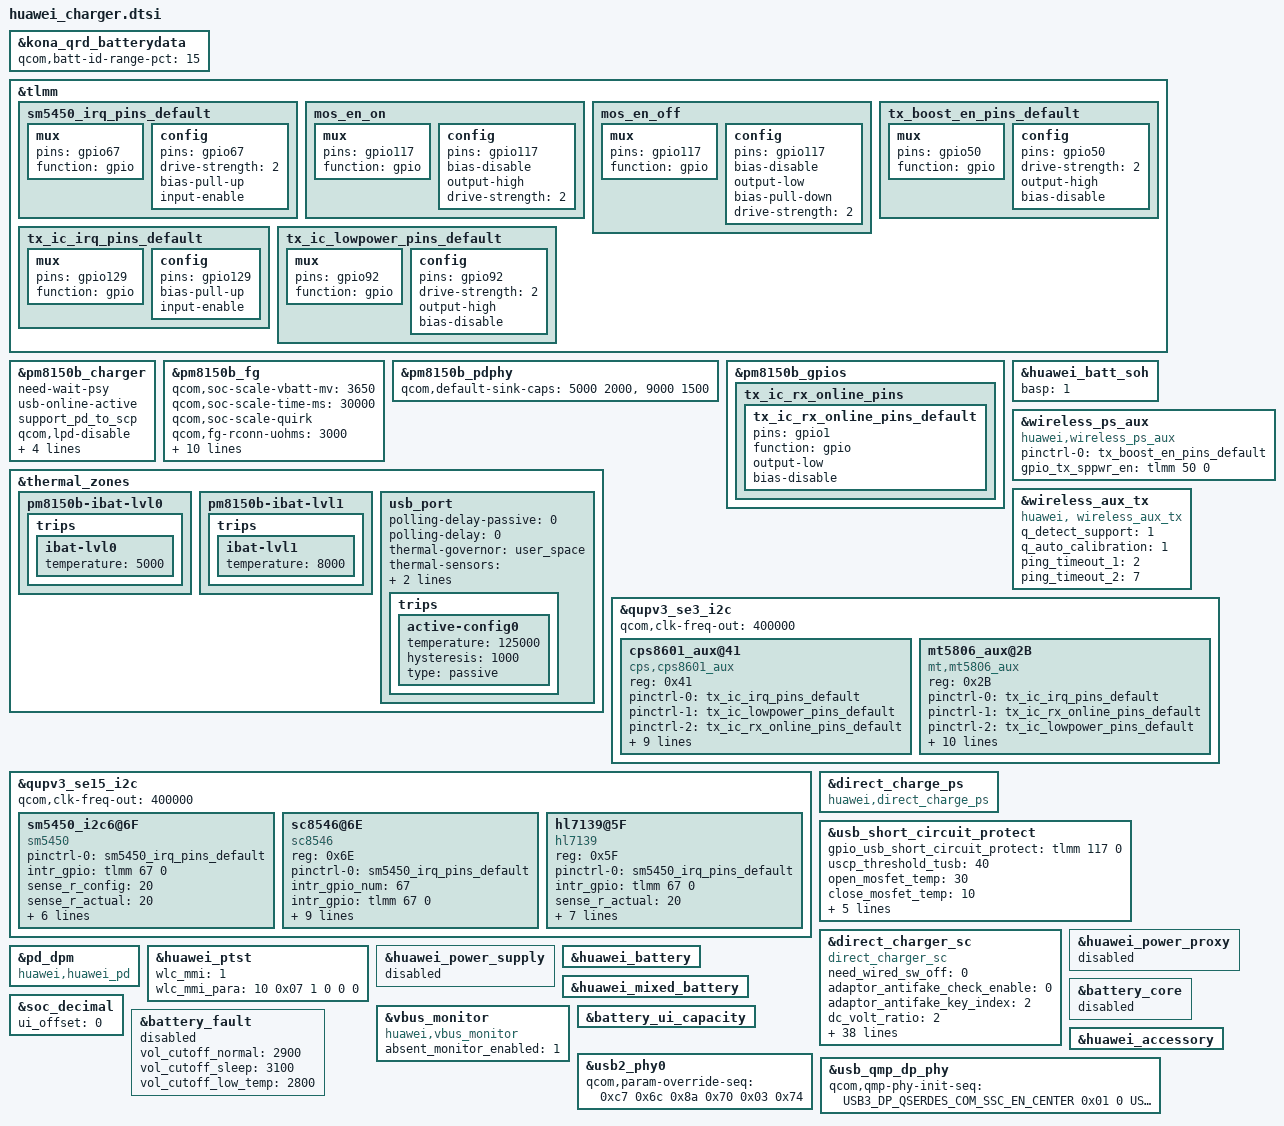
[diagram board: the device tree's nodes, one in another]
#include <dt-bindings/clock/qcom,gcc-kona.h>
#include <dt-bindings/phy/qcom,kona-qmp-usb3.h>

&kona_qrd_batterydata {
	qcom,batt-id-range-pct = <15>;
	#include "../../../huawei_charger/fg-gen4-batterydata-desayatl_7150_110k.dtsi"
	#include "../../../huawei_charger/fg-gen4-batterydata-sunwodacosmx_7150_200k.dtsi"
};

&tlmm {
	sm5450_irq_pins_default: sm5450_irq_pins_default {
		mux {
			pins = "gpio67";
			function = "gpio";
		};
		config {
			pins = "gpio67";
			drive-strength = <2>;
			bias-pull-up;
			input-enable;
		};
	};

	mos_en_on: mos_en_on {
		mux {
			pins = "gpio117";
			function = "gpio";
		};

		config {
			pins = "gpio117";
			bias-disable;
			output-high;
			drive-strength = <2>; /* 2 MA */
		};
	};

	mos_en_off: mos_en_off {
		mux {
			pins = "gpio117";
			function = "gpio";
		};

		config {
			pins = "gpio117";
			bias-disable;
			output-low;
			bias-pull-down; /* PULL DOWN */
			drive-strength = <2>; /* 2 MA */
		};
	};

	tx_boost_en_pins_default: tx_boost_en_pins_default {
		mux {
			pins = "gpio50";
			function = "gpio";
		};
		config {
			pins = "gpio50";
			drive-strength = <2>;
			output-high;
			bias-disable;
		};
	};

	tx_ic_irq_pins_default: tx_ic_irq_pins_default {
		mux {
			pins = "gpio129";
			function = "gpio";
		};
		config {
			pins = "gpio129";
			bias-pull-up;
			input-enable;
		};
	};

	tx_ic_lowpower_pins_default: tx_ic_lowpower_pins_default {
		mux {
			pins = "gpio92";
			function = "gpio";
		};
		config {
			pins = "gpio92";
			drive-strength = <2>;
			output-high;
			bias-disable;
		};
	};
};

&pm8150b_charger {
	need-wait-psy;
	usb-online-active;
	support_pd_to_scp;
	qcom,lpd-disable;
	qcom,otg-cl-ua = <1500000>;
	qcom,chg-term-current-ma = <(-178)>;
	qcom,auto-recharge-soc = <98>;
	qcom,auto-recharge-vbat-mv = <4250>;
};

&pm8150b_fg{
	qcom,soc-scale-vbatt-mv = <3650>;
	qcom,soc-scale-time-ms = <30000>;
	qcom,soc-scale-quirk;
	qcom,fg-rconn-uohms = <3000>;
	qcom,fg-cutoff-voltage = <3450>;
	qcom,slope-limit-temp-threshold = <100>;
	qcom,slope-limit-coeffs = <2500 2500 2500 500>;
        qcom,fg-force-load-profile;
	soc-temp-filt;
	qcom,soc-hi-res;
	qcom,fg-sys-term-current = <(-600)>;
	io-channels = <&pm8150b_vadc ADC_BAT_THERM_PU1>;
	io-channel-names = "batt_therm";
	qcom,fg-temp-ir-for-current = <7500 55 6500 55 5500 55 4500 55 3500 50 2500 40 1500 30 500 20 0 10>;
};

&pm8150b_pdphy {
	qcom,default-sink-caps = <5000 2000>, /* 5V @ 2A */
				 <9000 1500>; /* 9V @ 2A */
};

&pm8150b_gpios {
	tx_ic_rx_online_pins {
		tx_ic_rx_online_pins_default: tx_ic_rx_online_pins_default {
				pins = "gpio1";
				function = "gpio";
				output-low;
				bias-disable;
		};
	};
};

&huawei_batt_soh {
	basp = <1>;
	status = "ok";
};

&thermal_zones {
	pm8150b-ibat-lvl0 {
		trips {
			ibat-lvl0 {
				temperature = <5000>;
			};
		};
	};

	pm8150b-ibat-lvl1 {
		trips {
			ibat-lvl1 {
				temperature = <8000>;
			};
		};
	};
};

&wireless_ps_aux {
	compatible = "huawei,wireless_ps_aux";
	pinctrl-names = "default";
	pinctrl-0 = <&tx_boost_en_pins_default>;
	gpio_tx_sppwr_en = <&tlmm 50 0>;
	status = "ok";
};

&wireless_aux_tx {
	compatible = "huawei, wireless_aux_tx";
	q_detect_support = <1>;
	q_auto_calibration = <1>;
	ping_timeout_1 = <2>;
	ping_timeout_2 = <7>;
	status = "ok";
};

&qupv3_se3_i2c {
	#address-cells = <1>;
	#size-cells = <0>;
	qcom,clk-freq-out = <400000>;
	status = "ok";

	cps8601_aux@41 {
		compatible = "cps,cps8601_aux";
		reg = <0x41>;
		pinctrl-names = "irq", "lowpower", "rx_online";
		pinctrl-0 = <&tx_ic_irq_pins_default>;
		pinctrl-1 = <&tx_ic_lowpower_pins_default>;
		pinctrl-2 = <&tx_ic_rx_online_pins_default>;
		interrupt-parent = <&tlmm>;
		interrupts = <129 0>;
		gpio_int = <&tlmm 129 0>;
		gpio_lowpower = <&tlmm 92 0>;
		gpio_rx_online = <&pm8150b_gpios 1 0>;
		tx_min_fop = /bits/ 16 <120>;
		tx_max_fop = /bits/ 16 <145>;
		tx_ploss_th0 = /bits/ 16 <2500>;
		tx_ploss_cnt = /bits/ 8 <5>;
		status = "ok";
	};

	mt5806_aux@2B {
		compatible = "mt,mt5806_aux";
		reg = <0x2B>;
		pinctrl-names = "irq", "lowpower", "rx_online";
		pinctrl-0 = <&tx_ic_irq_pins_default>;
		pinctrl-1 = <&tx_ic_rx_online_pins_default>;
		pinctrl-2 = <&tx_ic_lowpower_pins_default>;
		interrupt-parent = <&tlmm>;
		interrupts = <129 0>;
		gpio_int = <&tlmm 129 0>;
		gpio_lowpower = <&tlmm 92 0>;
		gpio_rx_online = <&pm8150b_gpios 1 0>;
		tx_ping_ocp_th = <800>;
		tx_min_fop = /bits/ 16 <120>;
		tx_max_fop = /bits/ 16 <145>;
		tx_ploss_th0 = /bits/ 16 <2500>;
		tx_ploss_cnt = /bits/ 8 <5>;
		status = "ok";
	};
};

&qupv3_se15_i2c {
	#address-cells = <1>;
	#size-cells = <0>;
	qcom,clk-freq-out = <400000>; /* if bq27z561_fg is used, i2c clock must be 100k(100000) */
	status = "ok";

	sm5450_i2c6@6F {
		compatible = "sm5450";
		pinctrl-names = "default";
		pinctrl-0 = <&sm5450_irq_pins_default>;
		intr_gpio = <&tlmm 67 0>;
		sense_r_config = <20>;
		sense_r_actual = <20>;
		fcp_support = <1>;
		scp_support = <1>;
		close_ibat_ocp = <1>;
		sc_ibus_ocp = <4000>;
		switching_frequency = <675>;
		reg = <0x6F>;
		status = "ok";
	};

	sc8546@6E {
		compatible = "sc8546";
		reg = <0x6E>;
		pinctrl-names = "default";
		pinctrl-0 = <&sm5450_irq_pins_default>;
		intr_gpio_num = <67>; /* direct defined GPIO num */
		intr_gpio = <&tlmm 67 0>;
		fcp_support = <1>;
		scp_support = <1>;
		ufcs_support = <1>;
		sense_r_actual = <20>;
		i2c_recovery = <1>;
		i2c_recovery_addr = <0x6F>;
		switching_frequency = <850>;
		switching_frequency_shift = <1>;
		ic_role = <0>;
		status = "ok";
	};

	hl7139@5F {
		compatible = "hl7139";
		reg = <0x5F>;
		pinctrl-names = "default";
		pinctrl-0 = <&sm5450_irq_pins_default>;
		intr_gpio = <&tlmm 67 0>;
		sense_r_actual = <20>;
		fcp_support = <1>;
		scp_support = <1>;
		sc_ibus_ocp = <4000>;
		close_ibat_ocp = <1>;
		ignore_discharge_flag = <1>;
		switching_frequency = <500>;
		ic_role = <0>;
		status = "ok";
	};
};

&direct_charge_ps {
	compatible = "huawei,direct_charge_ps";
	status = "ok";
};

&thermal_zones {
	usb_port {
		polling-delay-passive = <0>;
		polling-delay = <0>;
		thermal-governor = "user_space";
		thermal-sensors = <&pm8150b_adc_tm ADC_AMUX_THM3_PU2>;
		wake-capable-sensor;
		trips {
			active-config0 {
				temperature = <125000>;
				hysteresis = <1000>;
				type = "passive";
			};
		};
	};
};

&usb_short_circuit_protect {
	gpio_usb_short_circuit_protect = <&tlmm 117 0>;
	uscp_threshold_tusb = <40>;
	open_mosfet_temp = <30>;
	close_mosfet_temp = <10>;
	open_hiz_temp = <30>;
	interval_switch_temp = <15>;
	use_pinctrl; /* use pinctrl to open or close mos */
	pinctrl-names = "mos_en_on", "mos_en_off";
	pinctrl-0 = <&mos_en_on>;
	pinctrl-1 = <&mos_en_off>;
	status = "ok";
};

&direct_charger_sc{
	compatible = "direct_charger_sc";
	need_wired_sw_off = <0>;
	adaptor_antifake_check_enable = <0>;
	adaptor_antifake_key_index = <2>;
	dc_volt_ratio = <2>;
	max_adaptor_vset = <11000>;
	max_tadapt = <115>;
	max_tls = <115>;
	ibat_abnormal_th = <200>;
	first_cc_stage_timer_in_min = <10>;
	max_dc_bat_vol = <4380>;
	min_dc_bat_vol = <3550>;
	charge_control_interval = <5>;
	threshold_caculation_interval = <5>;
	safety_monitor_interval = <5>;
	scp_work_on_charger = <1>;
	init_adapter_vset = <8800>;
	init_delt_vset = <450>;
	init_delt_iset = <1000>;
	vstep = <20>;
	delta_err = <300>;
	vol_err_th = <500>;
	full_path_res_max = <500>;
	ctc_cable_full_path_res_max = <400>;
	standard_cable_full_path_res_max = <500>;
	max_current_for_none_standard_cable = <6000>;
	adaptor_leakage_current_th = <300>;
	stage_need_to_jump = "-1";
	compensate_r = <0>;
	cc_cable_detect_enable = <1>;
	cc_unsafe_sc_enable = <1>;
	is_show_ico_first = <1>;
	delta_err_10v2p25a = <150>;
	gain_curr_10v2a = <300>;
	volt_para =
		"4130", "5000", "4000",
		"4220", "5000", "4000",
		"4280", "4000", "2800",
		"4420", "2800", "1200";
	temp_para =
		"-32767", "10", "0",
		"10", "45", "5000",
		"45", "32767", "0";
	10v2p25a_cur_para =
		"-32767", "5500",  "2250",
		"5500",   "9000",  "2500",
		"9000",   "10000", "2250",
		"10000",  "10500", "2250",
		"10500",  "32767", "1500";
	resist_para =
		"0", "300", "6000",
		"300", "500", "4000";
	std_resist_para =
		"0", "300", "8200",
		"300", "500", "4000";
	status = "ok";
};

&huawei_power_proxy {
	status = "disabled";
};

&pd_dpm {
	compatible = "huawei,huawei_pd";
	status = "ok";
};

&huawei_ptst {
	wlc_mmi = <1>;
	wlc_mmi_para = <10 0x07 1 0 0 0>;
	status = "ok";
};

&huawei_power_supply {
	status = "disabled";
};

&huawei_battery {
	status = "ok";
};

&huawei_mixed_battery {
	status = "ok";
};

&battery_core {
	status = "disabled";
};

&vbus_monitor {
	compatible = "huawei,vbus_monitor";
	absent_monitor_enabled = <1>;
	status = "ok";
};

&battery_ui_capacity {
	status = "ok";
};

&soc_decimal {
	ui_offset = <0>;
	status = "ok";
};

&battery_fault {
	vol_cutoff_normal = <2900>;
	vol_cutoff_sleep = <3100>;
	vol_cutoff_low_temp = <2800>;
	status = "disabled";
};

&huawei_accessory {
	status = "ok";
};

&usb2_phy0 {
	qcom,param-override-seq =
		<0xc7 0x6c
		0x8a 0x70
		0x03 0x74>;
};

&usb_qmp_dp_phy {
		qcom,qmp-phy-init-seq =
			/* <reg_offset, value, delay> */
			<USB3_DP_QSERDES_COM_SSC_EN_CENTER 0x01 0
			USB3_DP_QSERDES_COM_SSC_PER1 0x31 0
			USB3_DP_QSERDES_COM_SSC_PER2 0x01 0
			USB3_DP_QSERDES_COM_SSC_STEP_SIZE1_MODE0 0xDE 0
			USB3_DP_QSERDES_COM_SSC_STEP_SIZE2_MODE0 0x07 0
			USB3_DP_QSERDES_COM_SSC_STEP_SIZE1_MODE1 0xDE 0
			USB3_DP_QSERDES_COM_SSC_STEP_SIZE2_MODE1 0x07 0
			USB3_DP_QSERDES_COM_SYSCLK_BUF_ENABLE 0x0A 0
			USB3_DP_QSERDES_COM_CMN_IPTRIM 0x20 0
			USB3_DP_QSERDES_COM_CP_CTRL_MODE0 0x06 0
			USB3_DP_QSERDES_COM_CP_CTRL_MODE1 0x06 0
			USB3_DP_QSERDES_COM_PLL_RCTRL_MODE0 0x16 0
			USB3_DP_QSERDES_COM_PLL_RCTRL_MODE1 0x16 0
			USB3_DP_QSERDES_COM_PLL_CCTRL_MODE0 0x36 0
			USB3_DP_QSERDES_COM_PLL_CCTRL_MODE1 0x36 0
			USB3_DP_QSERDES_COM_SYSCLK_EN_SEL 0x1A 0
			USB3_DP_QSERDES_COM_LOCK_CMP_EN 0x04 0
			USB3_DP_QSERDES_COM_LOCK_CMP1_MODE0 0x14 0
			USB3_DP_QSERDES_COM_LOCK_CMP2_MODE0 0x34 0
			USB3_DP_QSERDES_COM_LOCK_CMP1_MODE1 0x34 0
			USB3_DP_QSERDES_COM_LOCK_CMP2_MODE1 0x82 0
			USB3_DP_QSERDES_COM_DEC_START_MODE0 0x82 0
			USB3_DP_QSERDES_COM_DEC_START_MODE1 0x82 0
			USB3_DP_QSERDES_COM_DIV_FRAC_START1_MODE0 0xAB 0
			USB3_DP_QSERDES_COM_DIV_FRAC_START2_MODE0 0xEA 0
			USB3_DP_QSERDES_COM_DIV_FRAC_START3_MODE0 0x02 0
			USB3_DP_QSERDES_COM_DIV_FRAC_START1_MODE1 0xAB 0
			USB3_DP_QSERDES_COM_DIV_FRAC_START2_MODE1 0xEA 0
			USB3_DP_QSERDES_COM_DIV_FRAC_START3_MODE1 0x02 0
			USB3_DP_QSERDES_COM_VCO_TUNE_MAP 0x02 0
			USB3_DP_QSERDES_COM_VCO_TUNE1_MODE0 0x24 0
			USB3_DP_QSERDES_COM_VCO_TUNE1_MODE1 0x24 0
			USB3_DP_QSERDES_COM_VCO_TUNE2_MODE1 0x02 0
			USB3_DP_QSERDES_COM_HSCLK_SEL 0x01 0
			USB3_DP_QSERDES_COM_CORECLK_DIV_MODE1 0x08 0
			USB3_DP_QSERDES_COM_BIN_VCOCAL_CMP_CODE1_MODE0 0xCA 0
			USB3_DP_QSERDES_COM_BIN_VCOCAL_CMP_CODE2_MODE0 0x1E 0
			USB3_DP_QSERDES_COM_BIN_VCOCAL_CMP_CODE1_MODE1 0xCA 0
			USB3_DP_QSERDES_COM_BIN_VCOCAL_CMP_CODE2_MODE1 0x1E 0
			USB3_DP_QSERDES_COM_BIN_VCOCAL_HSCLK_SEL 0x11 0
			USB3_DP_QSERDES_TXA_RES_CODE_LANE_TX 0x60 0
			USB3_DP_QSERDES_TXA_RES_CODE_LANE_RX 0x60 0
			USB3_DP_QSERDES_TXA_RES_CODE_LANE_OFFSET_TX 0x11 0
			USB3_DP_QSERDES_TXA_RES_CODE_LANE_OFFSET_RX 0x02 0
			USB3_DP_QSERDES_TXA_TX_EMP_POST1_LVL 0x3C 0
			USB3_DP_QSERDES_TXA_TX_DRV_LVL 0x3F 0
			USB3_DP_QSERDES_TXA_LANE_MODE_1 0xD5 0
			USB3_DP_QSERDES_TXA_LANE_MODE_2 0x00 0
			USB3_DP_QSERDES_TXA_RCV_DETECT_LVL_2 0x12 0
			USB3_DP_QSERDES_TXA_PI_QEC_CTRL 0x40 0
			USB3_DP_QSERDES_RXA_UCDR_FO_GAIN 0x09 0
			USB3_DP_QSERDES_RXA_UCDR_SO_GAIN 0x05 0
			USB3_DP_QSERDES_RXA_UCDR_FASTLOCK_FO_GAIN 0x2F 0
			USB3_DP_QSERDES_RXA_UCDR_SO_SATURATION_AND_ENABLE 0x7F 0
			USB3_DP_QSERDES_RXA_UCDR_FASTLOCK_COUNT_LOW 0xFF 0
			USB3_DP_QSERDES_RXA_UCDR_FASTLOCK_COUNT_HIGH 0x0F 0
			USB3_DP_QSERDES_RXA_UCDR_PI_CONTROLS 0x99 0
			USB3_DP_QSERDES_RXA_UCDR_SB2_THRESH1 0x08 0
			USB3_DP_QSERDES_RXA_UCDR_SB2_THRESH2 0x08 0
			USB3_DP_QSERDES_RXA_UCDR_SB2_GAIN1 0x00 0
			USB3_DP_QSERDES_RXA_UCDR_SB2_GAIN2 0x04 0
			USB3_DP_QSERDES_RXA_VGA_CAL_CNTRL1 0x54 0
			USB3_DP_QSERDES_RXA_VGA_CAL_CNTRL2 0x0C 0
			USB3_DP_QSERDES_RXA_RX_EQU_ADAPTOR_CNTRL2 0x0F 0
			USB3_DP_QSERDES_RXA_RX_EQU_ADAPTOR_CNTRL3 0x4A 0
			USB3_DP_QSERDES_RXA_RX_EQU_ADAPTOR_CNTRL4 0x0A 0
			USB3_DP_QSERDES_RXA_RX_IDAC_TSETTLE_LOW 0xC0 0
			USB3_DP_QSERDES_RXA_RX_IDAC_TSETTLE_HIGH 0x00 0
			USB3_DP_QSERDES_RXA_RX_EQ_OFFSET_ADAPTOR_CNTRL1 0x77 0
			USB3_DP_QSERDES_RXA_SIGDET_CNTRL 0x04 0
			USB3_DP_QSERDES_RXA_SIGDET_DEGLITCH_CNTRL 0x0E 0
			USB3_DP_QSERDES_RXA_RX_MODE_00_LOW 0xFF 0
			USB3_DP_QSERDES_RXA_RX_MODE_00_HIGH 0x7F 0
			USB3_DP_QSERDES_RXA_RX_MODE_00_HIGH2 0x7F 0
			USB3_DP_QSERDES_RXA_RX_MODE_00_HIGH3 0x7F 0
			USB3_DP_QSERDES_RXA_RX_MODE_00_HIGH4 0x97 0
			USB3_DP_QSERDES_RXA_RX_MODE_01_LOW 0xDC 0
			USB3_DP_QSERDES_RXA_RX_MODE_01_HIGH 0xDC 0
			USB3_DP_QSERDES_RXA_RX_MODE_01_HIGH2 0x5C 0
			USB3_DP_QSERDES_RXA_RX_MODE_01_HIGH3 0x7B 0
			USB3_DP_QSERDES_RXA_RX_MODE_01_HIGH4 0xB4 0
			USB3_DP_QSERDES_RXA_DFE_EN_TIMER 0x04 0
			USB3_DP_QSERDES_RXA_DFE_CTLE_POST_CAL_OFFSET 0x38 0
			USB3_DP_QSERDES_RXA_AUX_DATA_TCOARSE_TFINE 0xA0 0
			USB3_DP_QSERDES_RXA_DCC_CTRL1 0x0C 0
			USB3_DP_QSERDES_RXA_GM_CAL 0x1F 0
			USB3_DP_QSERDES_RXA_VTH_CODE 0x10 0
			USB3_DP_QSERDES_TXB_RES_CODE_LANE_TX 0x60 0
			USB3_DP_QSERDES_TXB_RES_CODE_LANE_RX 0x60 0
			USB3_DP_QSERDES_TXB_RES_CODE_LANE_OFFSET_TX 0x11 0
			USB3_DP_QSERDES_TXB_RES_CODE_LANE_OFFSET_RX 0x02 0
			USB3_DP_QSERDES_TXB_TX_EMP_POST1_LVL 0x3C 0
			USB3_DP_QSERDES_TXB_TX_DRV_LVL 0x3F 0
			USB3_DP_QSERDES_TXB_LANE_MODE_1 0xD5 0
			USB3_DP_QSERDES_TXB_LANE_MODE_2 0x00 0
			USB3_DP_QSERDES_TXB_RCV_DETECT_LVL_2 0x12 0
			USB3_DP_QSERDES_TXB_PI_QEC_CTRL 0x54 0
			USB3_DP_QSERDES_RXB_UCDR_FO_GAIN 0x09 0
			USB3_DP_QSERDES_RXB_UCDR_SO_GAIN 0x05 0
			USB3_DP_QSERDES_RXB_UCDR_FASTLOCK_FO_GAIN 0x2F 0
			USB3_DP_QSERDES_RXB_UCDR_SO_SATURATION_AND_ENABLE 0x7F 0
			USB3_DP_QSERDES_RXB_UCDR_FASTLOCK_COUNT_LOW 0xFF 0
			USB3_DP_QSERDES_RXB_UCDR_FASTLOCK_COUNT_HIGH 0x0F 0
			USB3_DP_QSERDES_RXB_UCDR_PI_CONTROLS 0x99 0
			USB3_DP_QSERDES_RXB_UCDR_SB2_THRESH1 0x08 0
			USB3_DP_QSERDES_RXB_UCDR_SB2_THRESH2 0x08 0
			USB3_DP_QSERDES_RXB_UCDR_SB2_GAIN1 0x00 0
			USB3_DP_QSERDES_RXB_UCDR_SB2_GAIN2 0x04 0
			USB3_DP_QSERDES_RXB_VGA_CAL_CNTRL1 0x54 0
			USB3_DP_QSERDES_RXB_VGA_CAL_CNTRL2 0x0C 0
			USB3_DP_QSERDES_RXB_RX_EQU_ADAPTOR_CNTRL2 0x0F 0
			USB3_DP_QSERDES_RXB_RX_EQU_ADAPTOR_CNTRL3 0x4A 0
			USB3_DP_QSERDES_RXB_RX_EQU_ADAPTOR_CNTRL4 0x0A 0
			USB3_DP_QSERDES_RXB_RX_IDAC_TSETTLE_LOW 0xC0 0
			USB3_DP_QSERDES_RXB_RX_IDAC_TSETTLE_HIGH 0x00 0
			USB3_DP_QSERDES_RXB_RX_EQ_OFFSET_ADAPTOR_CNTRL1 0x77 0
			USB3_DP_QSERDES_RXB_SIGDET_CNTRL 0x04 0
			USB3_DP_QSERDES_RXB_SIGDET_DEGLITCH_CNTRL 0x0E 0
			USB3_DP_QSERDES_RXB_RX_MODE_00_LOW 0x7F 0
			USB3_DP_QSERDES_RXB_RX_MODE_00_HIGH 0xFF 0
			USB3_DP_QSERDES_RXB_RX_MODE_00_HIGH2 0x3F 0
			USB3_DP_QSERDES_RXB_RX_MODE_00_HIGH3 0x7F 0
			USB3_DP_QSERDES_RXB_RX_MODE_00_HIGH4 0xA6 0
			USB3_DP_QSERDES_RXB_RX_MODE_01_LOW 0xDC 0
			USB3_DP_QSERDES_RXB_RX_MODE_01_HIGH 0xDC 0
			USB3_DP_QSERDES_RXB_RX_MODE_01_HIGH2 0x5C 0
			USB3_DP_QSERDES_RXB_RX_MODE_01_HIGH3 0x7B 0
			USB3_DP_QSERDES_RXB_RX_MODE_01_HIGH4 0xB4 0
			USB3_DP_QSERDES_RXB_DFE_EN_TIMER 0x04 0
			USB3_DP_QSERDES_RXB_DFE_CTLE_POST_CAL_OFFSET 0x38 0
			USB3_DP_QSERDES_RXB_AUX_DATA_TCOARSE_TFINE 0xA0 0
			USB3_DP_QSERDES_RXB_DCC_CTRL1 0x0C 0
			USB3_DP_QSERDES_RXB_GM_CAL 0x1F 0
			USB3_DP_QSERDES_RXB_VTH_CODE 0x10 0
			USB3_DP_PCS_G12S1_TXMGN_V0 0x3F 0
			USB3_DP_PCS_G12S1_TXDEEMPH_M6DB 0x3C 0
			USB3_DP_PCS_G12S1_TXDEEMPH_M3P5DB 0x3C 0
			USB3_DP_PCS_LOCK_DETECT_CONFIG1 0xD0 0
			USB3_DP_PCS_LOCK_DETECT_CONFIG2 0x07 0
			USB3_DP_PCS_LOCK_DETECT_CONFIG3 0x20 0
			USB3_DP_PCS_LOCK_DETECT_CONFIG6 0x13 0
			USB3_DP_PCS_REFGEN_REQ_CONFIG1 0x21 0
			USB3_DP_PCS_RX_SIGDET_LVL 0xA9 0
			USB3_DP_PCS_CDR_RESET_TIME 0x0A 0
			USB3_DP_PCS_ALIGN_DETECT_CONFIG1 0x88 0
			USB3_DP_PCS_ALIGN_DETECT_CONFIG2 0x13 0
			USB3_DP_PCS_PCS_TX_RX_CONFIG 0x0C 0
			USB3_DP_PCS_EQ_CONFIG1 0x4B 0
			USB3_DP_PCS_EQ_CONFIG5 0x10 0
			USB3_DP_PCS_USB3_LFPS_DET_HIGH_COUNT_VAL 0xF8 0
			USB3_DP_PCS_USB3_RXEQTRAINING_DFE_TIME_S2 0x07 0
			0xffffffff 0xffffffff 0x00>;
};
